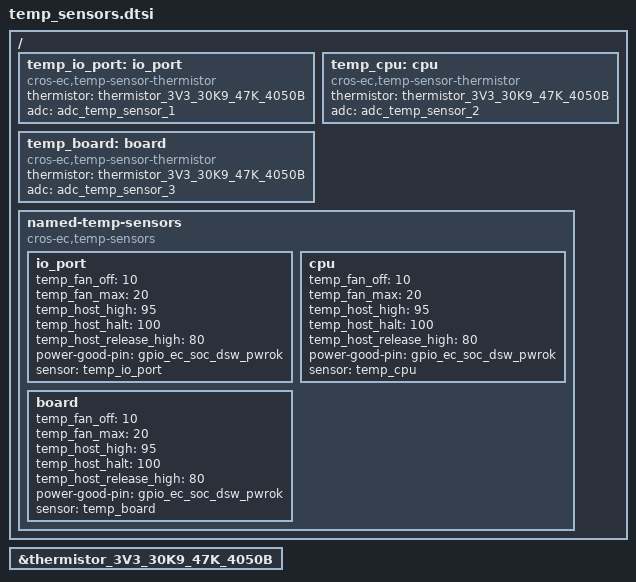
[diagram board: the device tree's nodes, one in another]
/* Copyright 2025 The ChromiumOS Authors
 * Use of this source code is governed by a BSD-style license that can be
 * found in the LICENSE file.
 */
 #include <cros/thermistor/thermistor.dtsi>

 / {
	 temp_io_port: io_port {
		 compatible = "cros-ec,temp-sensor-thermistor";
		 thermistor = <&thermistor_3V3_30K9_47K_4050B>;
		 adc = <&adc_temp_sensor_1>;
	 };
	 temp_cpu: cpu {
		compatible = "cros-ec,temp-sensor-thermistor";
		thermistor = <&thermistor_3V3_30K9_47K_4050B>;
		adc = <&adc_temp_sensor_2>;
	};
	 temp_board: board {
		compatible = "cros-ec,temp-sensor-thermistor";
		thermistor = <&thermistor_3V3_30K9_47K_4050B>;
		adc = <&adc_temp_sensor_3>;
	};

	named-temp-sensors {
		compatible = "cros-ec,temp-sensors";
		io_port {
			temp_fan_off = <10>;
			temp_fan_max = <20>;
			temp_host_high = <95>;
			temp_host_halt = <100>;
			temp_host_release_high = <80>;
			power-good-pin = <&gpio_ec_soc_dsw_pwrok>;
			sensor = <&temp_io_port>;
		};

		cpu {
			temp_fan_off = <10>;
			temp_fan_max = <20>;
			temp_host_high = <95>;
			temp_host_halt = <100>;
			temp_host_release_high = <80>;
			power-good-pin = <&gpio_ec_soc_dsw_pwrok>;
			sensor = <&temp_cpu>;
		};

		board {
			temp_fan_off = <10>;
			temp_fan_max = <20>;
			temp_host_high = <95>;
			temp_host_halt = <100>;
			temp_host_release_high = <80>;
			power-good-pin = <&gpio_ec_soc_dsw_pwrok>;
			sensor = <&temp_board>;
		};
	};
};

&thermistor_3V3_30K9_47K_4050B {
	status = "okay";
};
